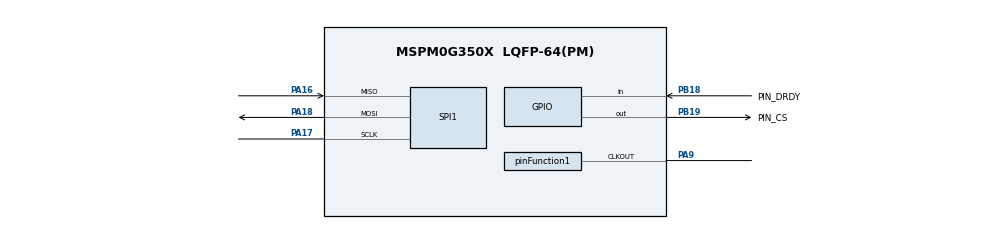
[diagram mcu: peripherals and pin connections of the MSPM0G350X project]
/**
 * @cliArgs --device "MSPM0G350X" --part "Default" --package "LQFP-64(PM)" --product "mspm0_sdk@2.05.01.01"
 * @versions {"tool":"1.24.0+4110"}
 */

/**
 * Import the modules used in this configuration.
 */
const GPIO   = scripting.addModule("/ti/driverlib/GPIO", {}, false);
const GPIO1  = GPIO.addInstance();
const SPI    = scripting.addModule("/ti/driverlib/SPI", {}, false);
const SPI1   = SPI.addInstance();
const SYSCTL = scripting.addModule("/ti/driverlib/SYSCTL");

/**
 * Write custom configuration values to the imported modules.
 */
const divider1       = system.clockTree["EXCLKDIV"];
divider1.divideValue = 4;

const divider9       = system.clockTree["UDIV"];
divider9.divideValue = 2;

const gate4  = system.clockTree["EXCLKGATE"];
gate4.enable = true;

const multiplier2         = system.clockTree["PLL_QDIV"];
multiplier2.multiplyValue = 4;

const mux3       = system.clockTree["EXCLKMUX"];
mux3.inputSelect = "EXCLKMUX_HFCLK";

const mux4       = system.clockTree["EXHFMUX"];
mux4.inputSelect = "EXHFMUX_XTAL";

const mux8       = system.clockTree["HSCLKMUX"];
mux8.inputSelect = "HSCLKMUX_SYSPLL0";

const mux12       = system.clockTree["SYSPLLMUX"];
mux12.inputSelect = "zSYSPLLMUX_HFCLK";

const pinFunction1                        = system.clockTree["CLKOUT"];
pinFunction1.enable                       = true;
pinFunction1.peripheral.$assign           = "SYSCTL";
pinFunction1.peripheral.clkOutPin.$assign = "PA9";

const pinFunction4        = system.clockTree["HFXT"];
pinFunction4.inputFreq    = 40;
pinFunction4.enable       = true;
pinFunction4.HFXTStartup  = 16;
pinFunction4.HFCLKMonitor = true;

GPIO1.$name                         = "GPIO_ADS";
GPIO1.associatedPins.create(2);
GPIO1.associatedPins[0].$name       = "PIN_DRDY";
GPIO1.associatedPins[0].direction   = "INPUT";
GPIO1.associatedPins[0].pin.$assign = "PB18";
GPIO1.associatedPins[1].$name       = "PIN_CS";
GPIO1.associatedPins[1].pin.$assign = "PB19";

const Board = scripting.addModule("/ti/driverlib/Board", {}, false);

SPI1.$name                              = "SPI_ADS";
SPI1.frameFormat                        = "MOTO3";
SPI1.phase                              = "1";
SPI1.targetBitRate                      = 20000000;
SPI1.sclkPinConfig.$name                = "ti_driverlib_gpio_GPIOPinGeneric0";
SPI1.sclkPinConfig.direction            = scripting.forceWrite("OUTPUT");
SPI1.sclkPinConfig.onlyInternalResistor = scripting.forceWrite(false);
SPI1.sclkPinConfig.passedPeripheralType = scripting.forceWrite("Digital");
SPI1.mosiPinConfig.$name                = "ti_driverlib_gpio_GPIOPinGeneric1";
SPI1.mosiPinConfig.direction            = scripting.forceWrite("OUTPUT");
SPI1.mosiPinConfig.hideOutputInversion  = scripting.forceWrite(false);
SPI1.mosiPinConfig.onlyInternalResistor = scripting.forceWrite(false);
SPI1.mosiPinConfig.passedPeripheralType = scripting.forceWrite("Digital");
SPI1.misoPinConfig.$name                = "ti_driverlib_gpio_GPIOPinGeneric2";
SPI1.misoPinConfig.onlyInternalResistor = scripting.forceWrite(false);
SPI1.misoPinConfig.passedPeripheralType = scripting.forceWrite("Digital");
SPI1.peripheral.$assign                 = "SPI1";
SPI1.peripheral.sclkPin.$assign         = "PA17";
SPI1.peripheral.mosiPin.$assign         = "PA18";
SPI1.peripheral.misoPin.$assign         = "PA16";

SYSCTL.forceDefaultClkConfig = true;
SYSCTL.clockTreeEn           = true;

/**
 * Pinmux solution for unlocked pins/peripherals. This ensures that minor changes to the automatic solver in a future
 * version of the tool will not impact the pinmux you originally saw.  These lines can be completely deleted in order to
 * re-solve from scratch.
 */
pinFunction4.peripheral.$suggestSolution           = "SYSCTL";
pinFunction4.peripheral.hfxInPin.$suggestSolution  = "PA5";
pinFunction4.peripheral.hfxOutPin.$suggestSolution = "PA6";
Board.peripheral.$suggestSolution                  = "DEBUGSS";
Board.peripheral.swclkPin.$suggestSolution         = "PA20";
Board.peripheral.swdioPin.$suggestSolution         = "PA19";
